# N575F145_v1 register map
File version: 1.0
Registers are 32-bit, read-write, reset 0x0 unless marked. A register's access mark holds for its fields unless they carry their own. Offsets are from the block's base; [hi:lo] are bit positions; {n}, {i} and the like mark numbered series; 'fields as' and 'values as' point back to an identical list.

## GP — GPIO Register Map
Base 0x50004000
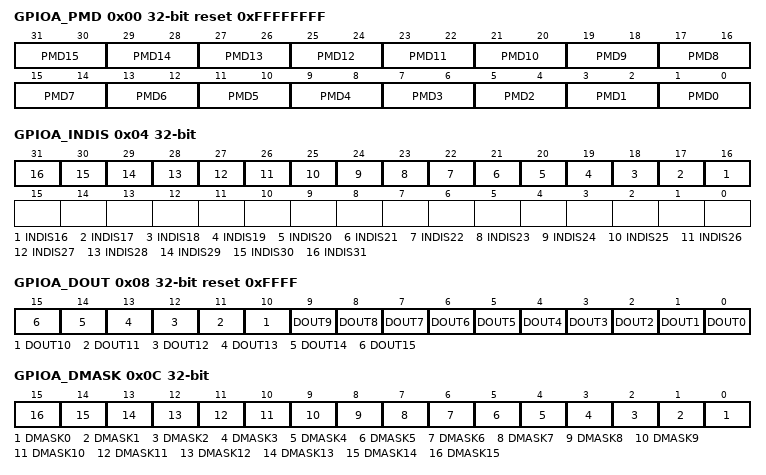
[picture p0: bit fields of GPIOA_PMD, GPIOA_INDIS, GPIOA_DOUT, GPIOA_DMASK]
0x00 GPIOA_PMD reset 0xFFFFFFFF — GPIO Port A Pin I/O Mode Control
  [all] fields
    0=GPIO port [n] pin is in INPUT mode; 1=GPIO port [n] pin is in OUTPUT mode; 2=GPIO port [n] pin is in Open-Drain mode; 3=GPIO port [n] pin is in Quasi-bidirectional mode
  [2n+1:2n] PMD{n} (n=0..15) — GPIOx I/O Pin[n] Mode Control. Determine each I/O type of GPIOx pins.
0x04 GPIOA_INDIS — GPIO Port A Pin Digital Input Disable
  [all] fields
    0=Enable IO digital input path (Default); 1=Disable IO digital input path (low leakage mode)
  [n] INDIS{n} (n=16..31) — GPIOx Pin[n] OFF Digital Input Path Enable
0x08 GPIOA_DOUT reset 0xFFFF — GPIO Port A Data Output Value
  [all] fields
    0=GPIO port [A/B] Pin[n] will drive Low if the corresponding output mode bit is set; 1=GPIO port [A/B] Pin[n] will drive High if the corresponding output mode bit is set
  [n] DOUT{n} (n=0..15) — GPIOx Pin[n] Output Value. Each of these bits controls the status of a GPIO pin when the GPIO pin is configured as output, open-drain or quasi-bidirectional mode.
0x0C GPIOA_DMASK — GPIO Port A Data Output Write Mask
  [all] fields
    0=The corresponding GPIO_DOUT[n] bit can be updated; 1=The corresponding GPIO_DOUT[n] bit is read only
  [n] DMASK{n} (n=0..15) — Port [A/B] Data Output Write Mask. These bits are used to protect the corresponding register of GPIOx_DOUT bit[n] . When set the DMASK bit[n] to "1", the corresponding DOUTn bit is write protected.
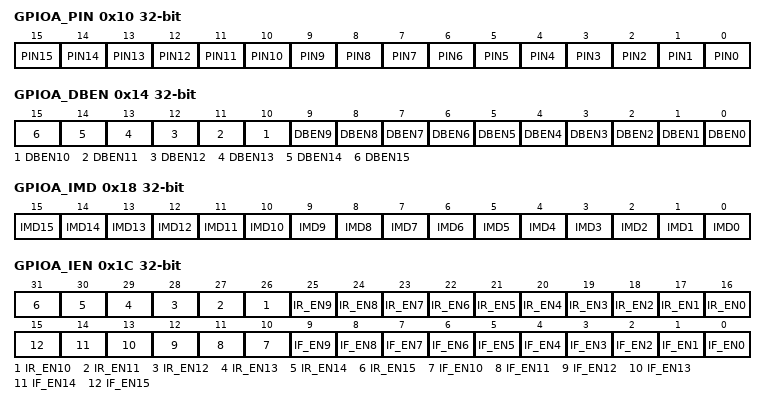
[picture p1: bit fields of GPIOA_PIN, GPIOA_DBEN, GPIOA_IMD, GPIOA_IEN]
0x10 GPIOA_PIN ro (reset mask 0xFFFF0000) — GPIO Port A Pin Value
  [n] PIN{n} (n=0..15) — Port [A/B] Pin Values. The value read from each of these bit reflects the actual status of the respective GPIO pin
0x14 GPIOA_DBEN — GPIO Port A De-bounce Enable
  [all] fields
    0=The bit[n] de-bounce function is disabled; 1=The bit[n] de-bounce function is enabled
  [n] DBEN{n} (n=0..15) — Port [A/B] Input Signal De-bounce Enable. DBEN[n]used to enable the de-bounce function for each corresponding bit. For an edge triggered interrupt to be generated, input signal must be valid for two consecutive de-bounce periods. The de-bounce time is controlled by the DBNCECON register. The DBEN[n] is used for "edge-trigger" interrupt only; it is ignored for "level trigger" interrupt
0x18 GPIOA_IMD — GPIO Port A Interrupt Mode Control
  [all] fields
    0=Edge triggered interrupt; 1=Level triggered interrupt
  [n] IMD{n} (n=0..15) — Port [A/B] Edge Or Level Detection Interrupt Control. IMD[n] used to control whether the interrupt mode is level triggered or edge triggered. If the interrupt mode is edge triggered, edge de-bounce is controlled by the DBEN register. If the interrupt mode is level triggered, the input source is sampled each clock to generate an interrupt. If level triggered interrupt is selected, then only one level can be selected in the GPIOX_IEN register. If both levels are set no interrupt will occur.
0x1C GPIOA_IEN — GPIO Port A Interrupt Enable
  [n+16] IR_EN{n} (n=0..15) — Port [A/B] Interrupt Enable by Input Rising Edge or Input Level High. IR_EN[n] is used to enable the rising/high interrupt for each of the corresponding GPIO pins. It also enables the pin wakeup function. If the interrupt is configured in level trigger mode, a level "high" will generate an interrupt. If the interrupt is configured in edge trigger mode, a state change from "low-to-high" will generate an interrupt. GPB.0 and GPB.1 trigger individual IRQ vectors (IRQ2/IRQ3) while remaining GPIO trigger a single interrupt vector IRQ4.
    0=Disable GPIOx[n] for level-high or low-to-high interrupt; 1=Enable GPIOx[n] for level-high or low-to-high interrupt
  [n] IF_EN{n} (n=0..15) — Port [A/B] Interrupt Enable by Input Falling Edge or Input Level Low. IF_EN[n] is used to enable the falling/low interrupt for each of the corresponding GPIO pins. It also enables the pin wakeup function. If the interrupt is configured in level trigger mode, a level "low" will generate an interrupt. If the interrupt is configured in edge trigger mode, a state change from "high-to-low" will generate an interrupt. GPB.0 and GPB.1 trigger individual IRQ vectors (IRQ2/IRQ3) while remaining GPIO trigger a single interrupt vector IRQ4.
    0=Disable GPIOx[n] for low-level or high-to-low interrupt; 1=Enable GPIOx[n] for low-level or high-to-low interrupt
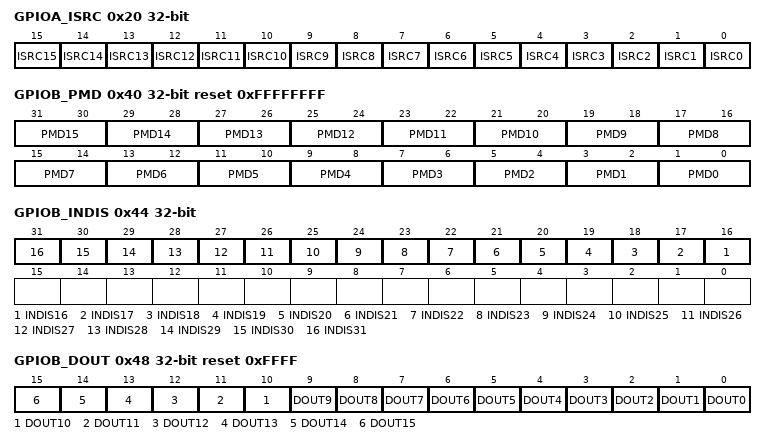
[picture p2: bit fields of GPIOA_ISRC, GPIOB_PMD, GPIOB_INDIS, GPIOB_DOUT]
0x20 GPIOA_ISRC — GPIO Port A Interrupt Trigger Source Indicator
  [n] ISRC{n} (n=0..15) — Port [A/B] Interrupt Trigger Source Indicator. Read : 1 = Indicates GPIOx[n] generated an interrupt. 0 = No interrupt from GPIOx[n]. Write : 1 = Clear the corresponding pending interrupt. 0 = No action
0x40 GPIOB_PMD reset 0xFFFFFFFF — GPIO Port A Pin I/O Mode Control
  fields as GPIOA_PMD
0x44 GPIOB_INDIS — GPIO Port A Pin Digital Input Disable
  fields as GPIOA_INDIS
0x48 GPIOB_DOUT reset 0xFFFF — GPIO Port A Data Output Value
  fields as GPIOA_DOUT
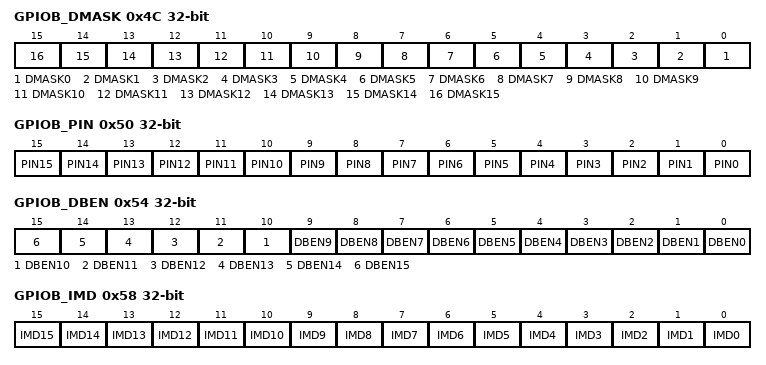
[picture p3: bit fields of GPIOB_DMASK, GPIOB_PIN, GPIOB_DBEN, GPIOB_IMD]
0x4C GPIOB_DMASK — GPIO Port A Data Output Write Mask
  fields as GPIOA_DMASK
0x50 GPIOB_PIN ro (reset mask 0xFFFF0000) — GPIO Port A Pin Value
  fields as GPIOA_PIN
0x54 GPIOB_DBEN — GPIO Port A De-bounce Enable
  fields as GPIOA_DBEN
0x58 GPIOB_IMD — GPIO Port A Interrupt Mode Control
  fields as GPIOA_IMD
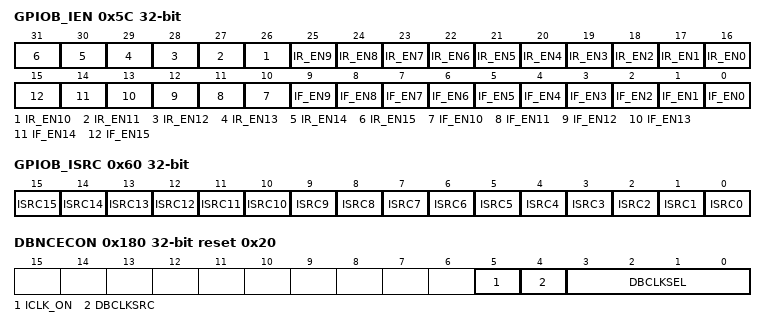
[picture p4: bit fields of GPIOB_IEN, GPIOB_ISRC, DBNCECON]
0x5C GPIOB_IEN — GPIO Port A Interrupt Enable
  fields as GPIOA_IEN
0x60 GPIOB_ISRC — GPIO Port A Interrupt Trigger Source Indicator
  fields as GPIOA_ISRC
0x180 DBNCECON reset 0x20 — Interrupt De-bounce Control
  [5] ICLK_ON — Interrupt Clock On Mode. Set this bit "0" will gate the clock to the interrupt generation circuit if the GPIOx[n] interrupt is disabled.
    0=disable the clock if the GPIOx[n] interrupt is disabled; 1=Interrupt generation clock always active
  [4] DBCLKSRC — De-bounce Counter Clock Source Select
    0=De-bounce counter clock source is HCLK; 1=De-bounce counter clock source is the internal 16 kHz clock
  [3:0] DBCLKSEL — De-bounce Sampling Cycle Selection. For edge level interrupt GPIO state is sampled every 2^(DBCLKSEL) de-bounce clocks. For example if DBCLKSRC = 6, then interrupt is sampled every 2^6 = 64 de-bounce clocks. If DBCLKSRC is 16KHz oscillator this would be a 64ms debounce.
